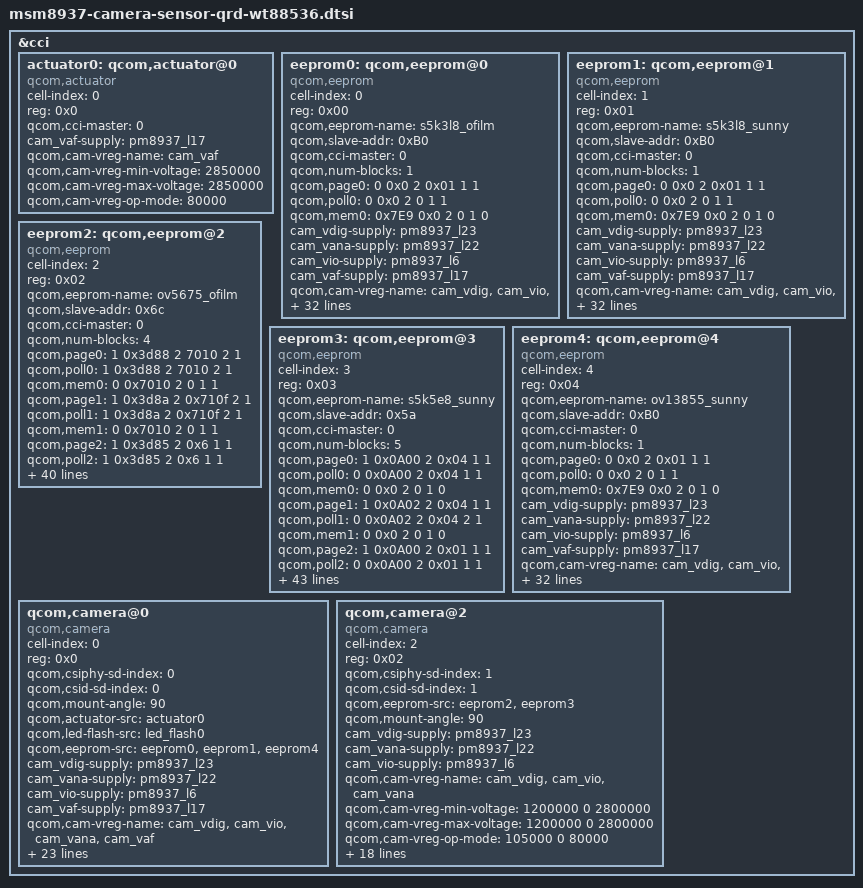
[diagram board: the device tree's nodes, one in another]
/*
 * Copyright (c) 2015, The Linux Foundation. All rights reserved.
 * Copyright (C) 2018 XiaoMi, Inc.
 *
 * This program is free software; you can redistribute it and/or modify
 * it under the terms of the GNU General Public License version 2 and
 * only version 2 as published by the Free Software Foundation.
 *
 * This program is distributed in the hope that it will be useful,
 * but WITHOUT ANY WARRANTY; without even the implied warranty of
 * MERCHANTABILITY or FITNESS FOR A PARTICULAR PURPOSE.  See the
 * GNU General Public License for more details.
 */
&cci {
	actuator0: qcom,actuator@0 {
		cell-index = <0>;
		reg = <0x0>;
		compatible = "qcom,actuator";
		qcom,cci-master = <0>;
		cam_vaf-supply = <&pm8937_l17>;
		qcom,cam-vreg-name = "cam_vaf";
		qcom,cam-vreg-min-voltage = <2850000>;
		qcom,cam-vreg-max-voltage = <2850000>;
		qcom,cam-vreg-op-mode = <80000>;
	};

	eeprom0: qcom,eeprom@0 {
		cell-index = <0>;
		reg = <0x00>;
		qcom,eeprom-name = "s5k3l8_ofilm";
		compatible = "qcom,eeprom";
		qcom,slave-addr = <0xB0>;
		qcom,cci-master = <0>;
		qcom,num-blocks = <1>;

		qcom,page0 = <0 0x0 2 0x01 1 1>;
		qcom,poll0 = <0 0x0 2 0 1 1>;
		qcom,mem0 = <0x7E9 0x0 2 0 1 0>;

		cam_vdig-supply = <&pm8937_l23>;
		cam_vana-supply = <&pm8937_l22>;
		cam_vio-supply = <&pm8937_l6>;
		cam_vaf-supply = <&pm8937_l17>;
		qcom,cam-vreg-name = "cam_vdig", "cam_vio", "cam_vana",
				"cam_vaf";
		qcom,cam-vreg-min-voltage = <1200000 1800000 2800000 2850000>;
		qcom,cam-vreg-max-voltage = <1200000 1800000 2800000 2850000>;
		qcom,cam-vreg-op-mode = <200000 200000 80000 100000>;
		pinctrl-names = "cam_default", "cam_suspend";
		pinctrl-0 = <&cam_sensor_mclk0_default &cam_sensor_rear_default>;
		pinctrl-1 = <&cam_sensor_mclk0_sleep &cam_sensor_rear_sleep>;
		gpios = <&tlmm 26 0>,
				<&tlmm 36 0>,
				<&tlmm 35 0>;
		qcom,gpio-reset = <1>;
		qcom,gpio-standby = <2>;
		qcom,gpio-req-tbl-num = <0 1 2>;
		qcom,gpio-req-tbl-flags = <1 0 0>;
		qcom,gpio-req-tbl-label = "CAMIF_MCLK0",
				"MCAM_RESET0",
				"MCAM_STANDBY0";

		qcom,cam-power-seq-type = "sensor_vreg",
				"sensor_vreg", "sensor_vreg", "sensor_vreg",
				"sensor_clk",
				"sensor_gpio", "sensor_gpio",
				"sensor_gpio", "sensor_gpio";
		qcom,cam-power-seq-val = "cam_vio",
				"cam_vana", "cam_vdig", "cam_vaf",
				"sensor_cam_mclk",
				"sensor_gpio_reset",
				"sensor_gpio_standby",
				"sensor_gpio_reset",
				"sensor_gpio_standby";
		qcom,cam-power-seq-cfg-val = <1 1 1 1 24000000 0 0 1 1>;
		qcom,cam-power-seq-delay = <1 1 5 1 10 5 5 5 5>;
		status = "ok";
		clocks = <&clock_gcc clk_mclk0_clk_src>,
				<&clock_gcc clk_gcc_camss_mclk0_clk>;
		clock-names = "cam_src_clk", "cam_clk";
		qcom,clock-rates = <24000000 0>;
	};

	eeprom1: qcom,eeprom@1 {
		cell-index = <1>;
		reg = <0x01>;
		qcom,eeprom-name = "s5k3l8_sunny";
		compatible = "qcom,eeprom";
		qcom,slave-addr = <0xB0>;
		qcom,cci-master = <0>;
		qcom,num-blocks = <1>;

		qcom,page0 = <0 0x0 2 0x01 1 1>;
		qcom,poll0 = <0 0x0 2 0 1 1>;
		qcom,mem0 = <0x7E9 0x0 2 0 1 0>;

		cam_vdig-supply = <&pm8937_l23>;
		cam_vana-supply = <&pm8937_l22>;
		cam_vio-supply = <&pm8937_l6>;
		cam_vaf-supply = <&pm8937_l17>;
		qcom,cam-vreg-name = "cam_vdig", "cam_vio", "cam_vana",
				"cam_vaf";
		qcom,cam-vreg-min-voltage = <1200000 1800000 2800000 2850000>;
		qcom,cam-vreg-max-voltage = <1200000 1800000 2800000 2850000>;
		qcom,cam-vreg-op-mode = <200000 200000 80000 100000>;
		pinctrl-names = "cam_default", "cam_suspend";
		pinctrl-0 = <&cam_sensor_mclk0_default &cam_sensor_rear_default>;
		pinctrl-1 = <&cam_sensor_mclk0_sleep &cam_sensor_rear_sleep>;
		gpios = <&tlmm 26 0>,
				<&tlmm 36 0>,
				<&tlmm 35 0>;
		qcom,gpio-reset = <1>;
		qcom,gpio-standby = <2>;
		qcom,gpio-req-tbl-num = <0 1 2>;
		qcom,gpio-req-tbl-flags = <1 0 0>;
		qcom,gpio-req-tbl-label = "CAMIF_MCLK0",
				"MCAM_RESET0",
				"MCAM_STANDBY0";

		qcom,cam-power-seq-type = "sensor_vreg",
				"sensor_vreg", "sensor_vreg", "sensor_vreg",
				"sensor_clk",
				"sensor_gpio", "sensor_gpio",
				"sensor_gpio", "sensor_gpio";
		qcom,cam-power-seq-val = "cam_vio",
				"cam_vana", "cam_vdig", "cam_vaf",
				"sensor_cam_mclk",
				"sensor_gpio_reset",
				"sensor_gpio_standby",
				"sensor_gpio_reset",
				"sensor_gpio_standby";
		qcom,cam-power-seq-cfg-val = <1 1 1 1 24000000 0 0 1 1>;
		qcom,cam-power-seq-delay = <1 1 5 5 10 5 5 5 5>;
		status = "ok";
		clocks = <&clock_gcc clk_mclk0_clk_src>,
				<&clock_gcc clk_gcc_camss_mclk0_clk>;
		clock-names = "cam_src_clk", "cam_clk";
		qcom,clock-rates = <24000000 0>;
	};

	eeprom2: qcom,eeprom@2{
		cell-index = <2>;
		reg = <0x02>;
		qcom,eeprom-name = "ov5675_ofilm";
		compatible = "qcom,eeprom";
		qcom,slave-addr = <0x6c>;
		qcom,cci-master = <0>;
		qcom,num-blocks = <4>;

		qcom,page0 = <1 0x3d88 2 7010 2 1>;
		qcom,poll0 = <1 0x3d88 2 7010 2 1>;
		qcom,mem0 = <0 0x7010 2 0 1 1>;
		qcom,page1 = <1 0x3d8a 2 0x710f 2 1>;
		qcom,poll1 = <1 0x3d8a 2 0x710f 2 1>;
		qcom,mem1 = <0 0x7010 2 0 1 1>;
		qcom,page2 = <1 0x3d85 2 0x6 1 1>;
		qcom,poll2 = <1 0x3d85 2 0x6 1 1>;
		qcom,mem2 = <0 0x7010 2 0 1 1>;
		qcom,page3 = <1 0x0100 2 0x1 1 1>;
		qcom,poll3 = <0 0x0100 2 0x1 1 1>;
		qcom,mem3 = <0x18 0x7010 2 0 1 1>;

		cam_vdig-supply = <&pm8937_l23>;
		cam_vana-supply = <&pm8937_l22>;
		cam_vio-supply = <&pm8937_l6>;
		qcom,cam-vreg-name = "cam_vdig", "cam_vio", "cam_vana";
		qcom,cam-vreg-min-voltage = <1200000 1800000 2800000>;
		qcom,cam-vreg-max-voltage = <1200000 1800000 2800000>;
		qcom,cam-vreg-op-mode = <200000 80000 100000>;
		qcom,gpio-no-mux = <0>;
		pinctrl-names = "cam_default", "cam_suspend";
		pinctrl-0 = <&cam_sensor_mclk2_default
				&cam_sensor_front1_default>;
		pinctrl-1 = <&cam_sensor_mclk2_sleep
				&cam_sensor_front1_sleep>;
		gpios = <&tlmm 28 0>,
				<&tlmm 40 0>,
				<&tlmm 39 0>;
		qcom,gpio-reset = <1>;
		qcom,gpio-standby = <2>;
		qcom,gpio-req-tbl-num = <0 1 2>;
		qcom,gpio-req-tbl-flags = <1 0 0>;
		qcom,gpio-req-tbl-label = "CAMIF_MCLK2",
				"CAM_RESET2",
				"CAM_STANDBY2";
		qcom,cam-power-seq-type =
				"sensor_gpio",
				"sensor_gpio",
				"sensor_clk",
				"sensor_vreg",
				"sensor_vreg",
				"sensor_vreg",
				"sensor_gpio",
				"sensor_gpio";
		qcom,cam-power-seq-val =
				"sensor_gpio_reset",
				"sensor_gpio_standby",
				"sensor_cam_mclk",
				"cam_vdig",
				"cam_vana",
				"cam_vio",
				"sensor_gpio_reset",
				"sensor_gpio_standby";
		qcom,cam-power-seq-cfg-val = <0 0 24000000 1 1 1 1 1>;
		qcom,cam-power-seq-delay = <5 5 10 1 1 1 5 5>;
		status = "ok";
		clocks = <&clock_gcc clk_mclk2_clk_src>,
				<&clock_gcc clk_gcc_camss_mclk2_clk>;
		clock-names = "cam_src_clk", "cam_clk";
		qcom,clock-rates = <24000000 0>;
	};

	eeprom3: qcom,eeprom@3{
		cell-index = <3>;
		reg = <0x03>;
		qcom,eeprom-name = "s5k5e8_sunny";
		compatible = "qcom,eeprom";
		qcom,slave-addr = <0x5a>;
		qcom,cci-master = <0>;
		qcom,num-blocks = <5>;

		qcom,page0 = <1 0x0A00 2 0x04 1 1>;
		qcom,poll0 = <0 0x0A00 2 0x04 1 1>;
		qcom,mem0 = <0 0x0 2 0 1 0>;

		qcom,page1 = <1 0x0A02 2 0x04 1 1>;
		qcom,poll1 = <0 0x0A02 2 0x04 2 1>;
		qcom,mem1 = <0 0x0 2 0 1 0>;

		qcom,page2 = <1 0x0A00 2 0x01 1 1>;
		qcom,poll2 = <0 0x0A00 2 0x01 1 1>;
		qcom,mem2 = <24 0x0A04 2 0 1 1>;

		qcom,page3 = <1 0x0A00 2 0x04 1 1>;
		qcom,poll3 = <0 0x0A00 2 0x04 1 1>;
		qcom,mem3 = <0 0x0 2 0 1 0>;

		qcom,page4 = <1 0x0A00 2 0x00 1 1>;
		qcom,poll4 =   <0 0x0A00 2 0x00 1 0>;
		qcom,mem4 = <0 0x0 2 0 1 0>;

		cam_vdig-supply = <&pm8937_l23>;
		cam_vana-supply = <&pm8937_l22>;
		cam_vio-supply = <&pm8937_l6>;
		qcom,cam-vreg-name = "cam_vdig", "cam_vio", "cam_vana";
		qcom,cam-vreg-min-voltage = <1200000 1800000 2800000>;
		qcom,cam-vreg-max-voltage = <1200000 1800000 2800000>;
		qcom,cam-vreg-op-mode = <200000 80000 100000>;
		qcom,gpio-no-mux = <0>;
		pinctrl-names = "cam_default", "cam_suspend";
		pinctrl-0 = <&cam_sensor_mclk2_default
				&cam_sensor_front1_default>;
		pinctrl-1 = <&cam_sensor_mclk2_sleep
				&cam_sensor_front1_sleep>;
		gpios = <&tlmm 28 0>,
				<&tlmm 40 0>,
				<&tlmm 39 0>;
		qcom,gpio-reset = <1>;
		qcom,gpio-standby = <2>;
		qcom,gpio-req-tbl-num = <0 1 2>;
		qcom,gpio-req-tbl-flags = <1 0 0>;
		qcom,gpio-req-tbl-label = "CAMIF_MCLK2",
				"CAM_RESET2",
				"CAM_STANDBY2";
		qcom,cam-power-seq-type =
				"sensor_gpio",
				"sensor_gpio",
				"sensor_clk",
				"sensor_vreg",
				"sensor_vreg",
				"sensor_vreg",
				"sensor_gpio",
				"sensor_gpio";
		qcom,cam-power-seq-val =
				"sensor_gpio_reset",
				"sensor_gpio_standby",
				"sensor_cam_mclk",
				"cam_vdig",
				"cam_vana",
				"cam_vio",
				"sensor_gpio_reset",
				"sensor_gpio_standby";
		qcom,cam-power-seq-cfg-val = <0 0 24000000 1 1 1 1 1>;
		qcom,cam-power-seq-delay = <5 5 10 1 1 1 5 5>;
		status = "ok";
		clocks = <&clock_gcc clk_mclk2_clk_src>,
				<&clock_gcc clk_gcc_camss_mclk2_clk>;
		clock-names = "cam_src_clk", "cam_clk";
		qcom,clock-rates = <24000000 0>;
	};
	eeprom4: qcom,eeprom@4 {
		cell-index = <4>;
		reg = <0x04>;
		qcom,eeprom-name = "ov13855_sunny";
		compatible = "qcom,eeprom";
		qcom,slave-addr = <0xB0>;
		qcom,cci-master = <0>;
		qcom,num-blocks = <1>;

		qcom,page0 = <0 0x0 2 0x01 1 1>;
		qcom,poll0 = <0 0x0 2 0 1 1>;
		qcom,mem0 = <0x7E9 0x0 2 0 1 0>;

		cam_vdig-supply = <&pm8937_l23>;
		cam_vana-supply = <&pm8937_l22>;
		cam_vio-supply = <&pm8937_l6>;
		cam_vaf-supply = <&pm8937_l17>;
		qcom,cam-vreg-name = "cam_vdig", "cam_vio", "cam_vana",
				"cam_vaf";
		qcom,cam-vreg-min-voltage = <1200000 1800000 2800000 2850000>;
		qcom,cam-vreg-max-voltage = <1200000 1800000 2800000 2850000>;
		qcom,cam-vreg-op-mode = <200000 200000 80000 100000>;
		pinctrl-names = "cam_default", "cam_suspend";
		pinctrl-0 = <&cam_sensor_mclk0_default &cam_sensor_rear_default>;
		pinctrl-1 = <&cam_sensor_mclk0_sleep &cam_sensor_rear_sleep>;
		gpios = <&tlmm 26 0>,
				<&tlmm 36 0>,
				<&tlmm 35 0>;
		qcom,gpio-reset = <1>;
		qcom,gpio-standby = <2>;
		qcom,gpio-req-tbl-num = <0 1 2>;
		qcom,gpio-req-tbl-flags = <1 0 0>;
		qcom,gpio-req-tbl-label = "CAMIF_MCLK0",
				"MCAM_RESET0",
				"MCAM_STANDBY0";

		qcom,cam-power-seq-type = "sensor_vreg",
				"sensor_vreg", "sensor_vreg", "sensor_vreg",
				"sensor_clk",
				"sensor_gpio", "sensor_gpio",
				"sensor_gpio", "sensor_gpio";
		qcom,cam-power-seq-val = "cam_vio",
				"cam_vana", "cam_vdig", "cam_vaf",
				"sensor_cam_mclk",
				"sensor_gpio_reset",
				"sensor_gpio_standby",
				"sensor_gpio_reset",
				"sensor_gpio_standby";
		qcom,cam-power-seq-cfg-val = <1 1 1 1 24000000 0 0 1 1>;
		qcom,cam-power-seq-delay = <1 1 5 5 10 5 5 5 5>;
		status = "ok";
		clocks = <&clock_gcc clk_mclk0_clk_src>,
				<&clock_gcc clk_gcc_camss_mclk0_clk>;
		clock-names = "cam_src_clk", "cam_clk";
		qcom,clock-rates = <24000000 0>;
	};

	qcom,camera@0 {
		cell-index = <0>;
		compatible = "qcom,camera";
		reg = <0x0>;
		qcom,csiphy-sd-index = <0>;
		qcom,csid-sd-index = <0>;
		qcom,mount-angle = <90>;
		qcom,actuator-src = <&actuator0>;
		qcom,led-flash-src = <&led_flash0>;
		qcom,eeprom-src = <&eeprom0 &eeprom1 &eeprom4>;
		cam_vdig-supply = <&pm8937_l23>;
		cam_vana-supply = <&pm8937_l22>;
		cam_vio-supply = <&pm8937_l6>;
		cam_vaf-supply = <&pm8937_l17>;
		qcom,cam-vreg-name = "cam_vdig", "cam_vio", "cam_vana",
				"cam_vaf";
		qcom,cam-vreg-min-voltage = <1200000 1800000 2800000 2850000>;
		qcom,cam-vreg-max-voltage = <1200000 1800000 2800000 2850000>;
		qcom,cam-vreg-op-mode = <200000 80000 80000 100000>;
		pinctrl-names = "cam_default", "cam_suspend";
		pinctrl-0 = <&cam_sensor_mclk0_default
				&cam_sensor_rear_default>;
		pinctrl-1 = <&cam_sensor_mclk0_sleep
				&cam_sensor_rear_sleep>;
		gpios = <&tlmm 26 0>,
				<&tlmm 36 0>,
				<&tlmm 35 0>;
		qcom,gpio-reset = <1>;
		qcom,gpio-standby = <2>;
		qcom,gpio-req-tbl-num = <0 1 2>;
		qcom,gpio-req-tbl-flags = <1 0 0>;
		qcom,gpio-req-tbl-label = "CAMIF_MCLK0",
				"CAM_RESET0",
				"CAM_STANDBY0";
		qcom,sensor-position = <0>;
		qcom,sensor-mode = <0>;
		qcom,cci-master = <0>;
		clocks = <&clock_gcc clk_mclk0_clk_src>,
				<&clock_gcc clk_gcc_camss_mclk0_clk>;
		clock-names = "cam_src_clk", "cam_clk";
		qcom,clock-rates = <24000000 0>;
	};

	qcom,camera@2 {
		cell-index = <2>;
		compatible = "qcom,camera";
		reg = <0x02>;
		qcom,csiphy-sd-index = <1>;
		qcom,csid-sd-index = <1>;
		qcom,eeprom-src = <&eeprom2 &eeprom3>;
		qcom,mount-angle = <90>;
		cam_vdig-supply = <&pm8937_l23>;
		cam_vana-supply = <&pm8937_l22>;
		cam_vio-supply = <&pm8937_l6>;
		qcom,cam-vreg-name = "cam_vdig", "cam_vio", "cam_vana";
		qcom,cam-vreg-min-voltage = <1200000 0 2800000>;
		qcom,cam-vreg-max-voltage = <1200000 0 2800000>;
		qcom,cam-vreg-op-mode = <105000 0 80000>;
		qcom,gpio-no-mux = <0>;
		pinctrl-names = "cam_default", "cam_suspend";
		pinctrl-0 = <&cam_sensor_mclk2_default
				&cam_sensor_front1_default>;
		pinctrl-1 = <&cam_sensor_mclk2_sleep
				&cam_sensor_front1_sleep>;
		gpios = <&tlmm 28 0>,
				<&tlmm 40 0>,
				<&tlmm 39 0>;
		qcom,gpio-reset = <1>;
		qcom,gpio-standby = <2>;
		qcom,gpio-req-tbl-num = <0 1 2>;
		qcom,gpio-req-tbl-flags = <1 0 0>;
		qcom,gpio-req-tbl-label = "CAMIF_MCLK2",
				"CAM_RESET2",
				"CAM_STANDBY2";
		qcom,sensor-position = <1>;
		qcom,sensor-mode = <0>;
		qcom,cci-master = <0>;
		clocks = <&clock_gcc clk_mclk2_clk_src>,
				<&clock_gcc clk_gcc_camss_mclk2_clk>;
		clock-names = "cam_src_clk", "cam_clk";
		qcom,clock-rates = <24000000 0>;
	};
};
